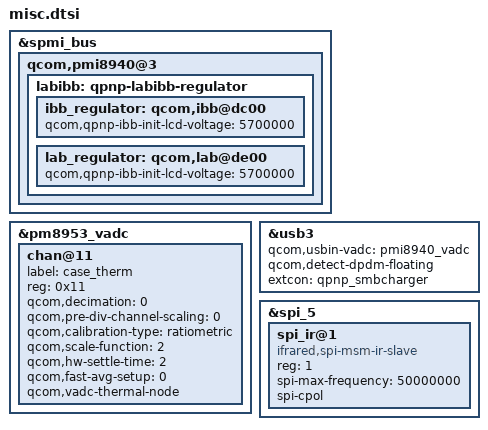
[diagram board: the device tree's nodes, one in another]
&spmi_bus {
	qcom,pmi8940@3 {
		labibb: qpnp-labibb-regulator {
			status = "ok";
			ibb_regulator: qcom,ibb@dc00 {
				/delete-property/
					qcom,qpnp-ibb-use-default-voltage;
				qcom,qpnp-ibb-init-lcd-voltage = <5700000>;
			};

			lab_regulator: qcom,lab@de00 {
				/delete-property/
					qcom,qpnp-ibb-use-default-voltage;
				qcom,qpnp-ibb-init-lcd-voltage = <5700000>;
			};
		};
	};
};

&pm8953_vadc {
chan@11 {
		label = "case_therm";
		reg = <0x11>;
		qcom,decimation = <0>;
		qcom,pre-div-channel-scaling = <0>;
		qcom,calibration-type = "ratiometric";
		qcom,scale-function = <2>;
		qcom,hw-settle-time = <2>;
		qcom,fast-avg-setup = <0>;
		qcom,vadc-thermal-node;
	};
};	

&usb3 {
	qcom,usbin-vadc = <&pmi8940_vadc>;
	qcom,detect-dpdm-floating;
	extcon = <&qpnp_smbcharger>;
};

&spi_5 {
	status = "ok";
	    spi_ir@1 {
	        compatible = "ifrared,spi-msm-ir-slave";
	        reg = <1>; /* Chip select 0 */
	        spi-max-frequency = <50000000>;
	        spi-cpol;
	        status = "ok";
	    };
};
